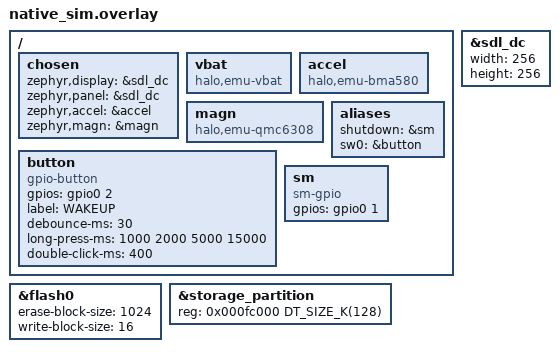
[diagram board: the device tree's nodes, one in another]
/*
 * Halo desktop emulator — native_sim devicetree overlay.
 * Passed via -DEXTRA_DTC_OVERLAY_FILE (emulator/build.sh); the firmware
 * tree is not modified. Shared by native_sim and native_sim_64.
 *
 * native_sim.dts already provides the flash simulator (flashcontroller0 /
 * flash0) with a fixed-partitions layout whose storage_partition node label
 * matches STORAGE_PARTITION in modules/halo/src/file_manager.c, and an
 * sdl_dc display controller wired to chosen zephyr,display. The flash
 * geometry and storage size are re-shaped below to mirror the hardware MRAM
 * (ticket 0004).
 */

/ {
	chosen {
		zephyr,display = &sdl_dc;
		/* lua_display.c:317 treats the panel as a separate device for
		 * blanking + PM suspend/resume; on emu the SDL display is
		 * both (MIPI_DSI/CDC200 paths are compiled out). PM calls on
		 * it return -ENOSYS, which lua_display already tolerates. */
		zephyr,panel = &sdl_dc;
		/* lua_imu.c grabs both at compile time (lua_imu.c:26-27);
		 * skeleton fakes from module/src/fake_sensors.c until 0012 */
		zephyr,accel = &accel;
		zephyr,magn = &magn;
	};

	/* Label is the contract: battery_manager.c:361 and lua_system.c:416
	 * DEVICE_DT_GET the `vbat` nodelabel (fixed values until 0011). */
	vbat: vbat {
		compatible = "halo,emu-vbat";
	};

	accel: accel {
		compatible = "halo,emu-bma580";
	};

	magn: magn {
		compatible = "halo,emu-qmc6308";
	};

	aliases {
		/*
		 * lua_system.c / lua_button.c DEVICE_DT_GET(DT_ALIAS(shutdown))
		 * unconditionally. Same node shape as halo.dts's `sm`, wired
		 * to the emulated GPIO to satisfy the sm-gpio binding, but
		 * driven by the emulator module's shutdown_emu.c (exits the
		 * process; the real driver is out via CONFIG_SM_GPIO=n).
		 */
		shutdown = &sm;
		/* lua_button.c:465 DEVICE_DT_GET(DT_ALIAS(sw0)) */
		sw0 = &button;
	};

	/*
	 * The firmware's own multi-level button driver
	 * (drivers/input/input_gpio_button.c) on the emulated GPIO
	 * controller. Timings mirror applications/halo/boards/halo.overlay.
	 * ACTIVE_HIGH (production is ACTIVE_LOW): gpio_emul inputs boot at 0,
	 * which must read "released" — ticket 0010's injection accounts for
	 * the polarity.
	 */
	button: button {
		compatible = "gpio-button";
		gpios = <&gpio0 2 GPIO_ACTIVE_HIGH>;
		label = "WAKEUP";
		debounce-ms = <30>;
		long-press-ms = <1000 2000 5000 15000>;
		double-click-ms = <400>;
	};

	sm: sm {
		compatible = "sm-gpio";
		gpios = <&gpio0 1 GPIO_ACTIVE_HIGH>;
	};
};

/*
 * Canvas PHYS_WIDTH/HEIGHT resolve from DT_CHOSEN(zephyr_display), so the
 * emulated panel size is set here (display HAL extraction: tickets 0007/0008).
 */
&sdl_dc {
	width = <256>;
	height = <256>;
};

/*
 * /lfs storage (ticket 0004): file_manager.c mounts littlefs on
 * FIXED_PARTITION(storage_partition) unmodified — flash_sim implements the
 * same flash API + page layout MRAM does. Match the Balletto MRAM geometry
 * (zephyr/dts/arm/alif/balletto_fpga_rtss_common.dtsi: erase-block 1024,
 * write-block 16) so littlefs computes the identical filesystem layout as
 * on hardware. littlefs defaults hold: prog/read 16 divides cache 64
 * divides block 1024, partition is a block multiple — no geometry warnings.
 * (native_sim's stock 4096/1 would also mount, but images would not be
 * interchangeable with device geometry.)
 */
&flash0 {
	erase-block-size = <1024>;
	write-block-size = <16>;
};

/*
 * Grow storage from native_sim's stock 16 KB to the hardware partition size
 * (halo.dts storage_partition: 128 KB). Same 0xfc000 start, extended in
 * place: nothing sits above it, and 0xfc000 + 128 KB ends well inside the
 * 2 MB flash0. The mcuboot/slot partitions below are unused on the emulator
 * (no MCUboot; OTA is out of scope until 0023).
 */
&storage_partition {
	reg = <0x000fc000 DT_SIZE_K(128)>;
};

/*
 * Placeholders: fake sensor / video / vbat / button nodes are added by
 * tickets 0010-0016 (button, battery, IMU, LED, audio, camera fakes).
 */
